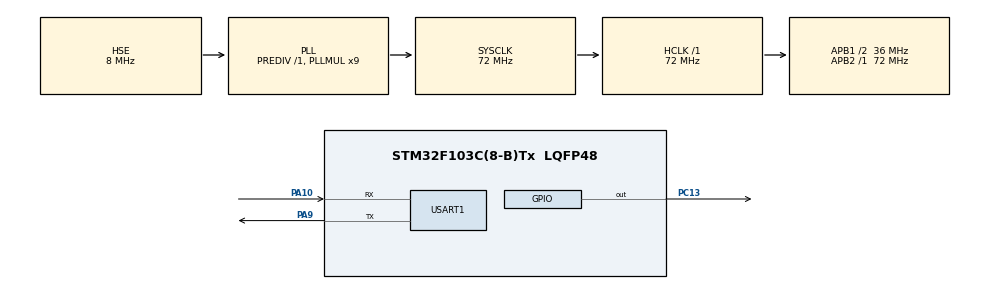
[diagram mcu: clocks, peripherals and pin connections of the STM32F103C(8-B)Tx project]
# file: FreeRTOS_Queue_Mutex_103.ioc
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FREERTOS.Mutexes01=myMutex,Static,myMutexControlBlock
FREERTOS.Queues01=myQueue,16,Zerg,0,Static,myQueueBuffer,myQueueControlBlock
FREERTOS.Tasks01=Print_Task,0,256,Start_Print_Task,Default,NULL,Static,Print_TaskBuffer,Print_TaskControlBlock;my_ON_Task,0,256,Start_ON_Task,Default,NULL,Static,my_ON_TaskBuffer,my_ON_TaskControlBlock;my_OFF_Task,0,256,Start_OFF_Task,Default,NULL,Static,myt_OFF_TaskBuffer,myt_OFF_TaskControlBlock
FREERTOS.configUSE_NEWLIB_REENTRANT=1
Mcu.Family=STM32F1
Mcu.Name=STM32F103C(8-B)Tx
Mcu.Package=LQFP48
NVIC.PriorityGroup=NVIC_PRIORITYGROUP_4
NVIC.TIM4_IRQn=true\:15\:0\:false\:false\:true\:false\:false\:true\:true
NVIC.TimeBase=TIM4_IRQn
NVIC.TimeBaseIP=TIM4
PA10.Mode=Asynchronous
PA10.Signal=USART1_RX
PA13.Mode=Serial_Wire
PA13.Signal=SYS_JTMS-SWDIO
PA14.Mode=Serial_Wire
PA14.Signal=SYS_JTCK-SWCLK
PA9.Mode=Asynchronous
PA9.Signal=USART1_TX
PC13-TAMPER-RTC.Signal=GPIO_Output
PD0-OSC_IN.Mode=HSE-External-Oscillator
PD0-OSC_IN.Signal=RCC_OSC_IN
PD1-OSC_OUT.Mode=HSE-External-Oscillator
PD1-OSC_OUT.Signal=RCC_OSC_OUT
ProjectManager.HeapSize=0x200
ProjectManager.StackSize=0x400
ProjectManager.TargetToolchain=STM32CubeIDE
RCC.AHBFreq_Value=72000000
RCC.APB1CLKDivider=RCC_HCLK_DIV2
RCC.APB1Freq_Value=36000000
RCC.APB1TimFreq_Value=72000000
RCC.APB2Freq_Value=72000000
RCC.APB2TimFreq_Value=72000000
RCC.HCLKFreq_Value=72000000
RCC.PLLMUL=RCC_PLL_MUL9
RCC.PLLSourceVirtual=RCC_PLLSOURCE_HSE
RCC.SYSCLKFreq_VALUE=72000000
RCC.SYSCLKSource=RCC_SYSCLKSOURCE_PLLCLK
RCC.USBFreq_Value=72000000
RTC.Date=11
RTC.Hours=15
RTC.Minutes=30
RTC.Month=RTC_MONTH_APRIL
RTC.WeekDay=RTC_WEEKDAY_TUESDAY
RTC.Year=23
USART1.VirtualMode=VM_ASYNC
VP_FREERTOS_VS_CMSIS_V1.Mode=CMSIS_V1
VP_RTC_VS_RTC_Activate.Mode=RTC_Enabled
VP_RTC_VS_RTC_Calendar.Mode=RTC_Calendar
VP_SYS_VS_tim4.Mode=TIM4
board=custom

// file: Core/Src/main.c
/* USER CODE BEGIN Header */
/**
 ******************************************************************************
 * @file           : main.c
 * @brief          : Main program body
 ******************************************************************************
 * @attention
 *
 * Copyright (c) 2023 STMicroelectronics.
 * All rights reserved.
 *
 * This software is licensed under terms that can be found in the LICENSE file
 * in the root directory of this software component.
 * If no LICENSE file comes with this software, it is provided AS-IS.
 *
 ******************************************************************************
 */
/* USER CODE END Header */
#include "main.h"
#include "cmsis_os.h"

/* USER CODE BEGIN Includes */
#include <stdio.h> /* для printf */

typedef struct {
	char mySharedResource[10];
} Zerg;
/* USER CODE END Includes */

RTC_HandleTypeDef hrtc;

UART_HandleTypeDef huart1;

osThreadId Print_TaskHandle;
uint32_t Print_TaskBuffer[256];
osStaticThreadDef_t Print_TaskControlBlock;
osThreadId my_ON_TaskHandle;
uint32_t my_ON_TaskBuffer[256];
osStaticThreadDef_t my_ON_TaskControlBlock;
osThreadId my_OFF_TaskHandle;
uint32_t myt_OFF_TaskBuffer[256];
osStaticThreadDef_t myt_OFF_TaskControlBlock;
osMessageQId myQueueHandle;
uint8_t myQueueBuffer[16 * sizeof(Zerg)];
osStaticMessageQDef_t myQueueControlBlock;
osMutexId myMutexHandle;
osStaticMutexDef_t myMutexControlBlock;

void SystemClock_Config(void);
static void MX_GPIO_Init(void);
static void MX_RTC_Init(void);
static void MX_USART1_UART_Init(void);
void Start_Print_Task(void const *argument);
void Start_ON_Task(void const *argument);
void Start_OFF_Task(void const *argument);

/* USER CODE BEGIN PFP */
int _write(int file, char *ptr, int len) {
	int i;
	HAL_UART_Transmit(&huart1, (uint8_t*) ptr, len, 50);
	for (i = 0; i < len; i++) {
		ITM_SendChar(*ptr++);
	}
	return len;
}
/* USER CODE END PFP */

int main(void) {

	/* MCU Configuration--------------------------------------------------------*/

	/* Reset of all peripherals, Initializes the Flash interface and the Systick. */
	HAL_Init();

	/* Configure the system clock */
	SystemClock_Config();

	/* Initialize all configured peripherals */
	MX_GPIO_Init();
	MX_RTC_Init();
	MX_USART1_UART_Init();

	/* Create the mutex(es) */
	/* definition and creation of myMutex */
	osMutexStaticDef(myMutex, &myMutexControlBlock);
	myMutexHandle = osMutexCreate(osMutex(myMutex));

	/* Create the queue(s) */
	/* definition and creation of myQueue */
	osMessageQStaticDef(myQueue, 16, Zerg, myQueueBuffer, &myQueueControlBlock);
	myQueueHandle = osMessageCreate(osMessageQ(myQueue), NULL);

	/* Create the thread(s) */
	/* definition and creation of Print_Task */
	osThreadStaticDef(Print_Task, Start_Print_Task, osPriorityNormal, 0, 256,
			Print_TaskBuffer, &Print_TaskControlBlock);
	Print_TaskHandle = osThreadCreate(osThread(Print_Task), NULL);

	/* definition and creation of my_ON_Task */
	osThreadStaticDef(my_ON_Task, Start_ON_Task, osPriorityNormal, 0, 256,
			my_ON_TaskBuffer, &my_ON_TaskControlBlock);
	my_ON_TaskHandle = osThreadCreate(osThread(my_ON_Task), NULL);

	/* definition and creation of my_OFF_Task */
	osThreadStaticDef(my_OFF_Task, Start_OFF_Task, osPriorityNormal, 0, 256,
			myt_OFF_TaskBuffer, &myt_OFF_TaskControlBlock);
	my_OFF_TaskHandle = osThreadCreate(osThread(my_OFF_Task), NULL);

	/* Start scheduler */
	osKernelStart();
	/* We should never get here as control is now taken by the scheduler */
	/* Infinite loop */
	while (1) {

	}
}

void SystemClock_Config(void) {
	RCC_OscInitTypeDef RCC_OscInitStruct = { 0 };
	RCC_ClkInitTypeDef RCC_ClkInitStruct = { 0 };
	RCC_PeriphCLKInitTypeDef PeriphClkInit = { 0 };

	/** Initializes the RCC Oscillators according to the specified parameters
	 * in the RCC_OscInitTypeDef structure.
	 */
	RCC_OscInitStruct.OscillatorType = RCC_OSCILLATORTYPE_LSI
			| RCC_OSCILLATORTYPE_HSE;
	RCC_OscInitStruct.HSEState = RCC_HSE_ON;
	RCC_OscInitStruct.HSEPredivValue = RCC_HSE_PREDIV_DIV1;
	RCC_OscInitStruct.HSIState = RCC_HSI_ON;
	RCC_OscInitStruct.LSIState = RCC_LSI_ON;
	RCC_OscInitStruct.PLL.PLLState = RCC_PLL_ON;
	RCC_OscInitStruct.PLL.PLLSource = RCC_PLLSOURCE_HSE;
	RCC_OscInitStruct.PLL.PLLMUL = RCC_PLL_MUL9;
	if (HAL_RCC_OscConfig(&RCC_OscInitStruct) != HAL_OK) {
		Error_Handler();
	}

	/** Initializes the CPU, AHB and APB buses clocks
	 */
	RCC_ClkInitStruct.ClockType = RCC_CLOCKTYPE_HCLK | RCC_CLOCKTYPE_SYSCLK
			| RCC_CLOCKTYPE_PCLK1 | RCC_CLOCKTYPE_PCLK2;
	RCC_ClkInitStruct.SYSCLKSource = RCC_SYSCLKSOURCE_PLLCLK;
	RCC_ClkInitStruct.AHBCLKDivider = RCC_SYSCLK_DIV1;
	RCC_ClkInitStruct.APB1CLKDivider = RCC_HCLK_DIV2;
	RCC_ClkInitStruct.APB2CLKDivider = RCC_HCLK_DIV1;

	if (HAL_RCC_ClockConfig(&RCC_ClkInitStruct, FLASH_LATENCY_2) != HAL_OK) {
		Error_Handler();
	}
	PeriphClkInit.PeriphClockSelection = RCC_PERIPHCLK_RTC;
	PeriphClkInit.RTCClockSelection = RCC_RTCCLKSOURCE_LSI;
	if (HAL_RCCEx_PeriphCLKConfig(&PeriphClkInit) != HAL_OK) {
		Error_Handler();
	}
}

static void MX_RTC_Init(void) {

	RTC_TimeTypeDef sTime = { 0 };
	RTC_DateTypeDef DateToUpdate = { 0 };

	/** Initialize RTC Only
	 */
	hrtc.Instance = RTC;
	hrtc.Init.AsynchPrediv = RTC_AUTO_1_SECOND;
	hrtc.Init.OutPut = RTC_OUTPUTSOURCE_ALARM;
	if (HAL_RTC_Init(&hrtc) != HAL_OK) {
		Error_Handler();
	}

	/** Initialize RTC and set the Time and Date
	 */
	sTime.Hours = 0x15;
	sTime.Minutes = 0x30;
	sTime.Seconds = 0x0;

	if (HAL_RTC_SetTime(&hrtc, &sTime, RTC_FORMAT_BCD) != HAL_OK) {
		Error_Handler();
	}
	DateToUpdate.WeekDay = RTC_WEEKDAY_TUESDAY;
	DateToUpdate.Month = RTC_MONTH_APRIL;
	DateToUpdate.Date = 0x11;
	DateToUpdate.Year = 0x23;

	if (HAL_RTC_SetDate(&hrtc, &DateToUpdate, RTC_FORMAT_BCD) != HAL_OK) {
		Error_Handler();
	}

}

static void MX_USART1_UART_Init(void) {

	huart1.Instance = USART1;
	huart1.Init.BaudRate = 115200;
	huart1.Init.WordLength = UART_WORDLENGTH_8B;
	huart1.Init.StopBits = UART_STOPBITS_1;
	huart1.Init.Parity = UART_PARITY_NONE;
	huart1.Init.Mode = UART_MODE_TX_RX;
	huart1.Init.HwFlowCtl = UART_HWCONTROL_NONE;
	huart1.Init.OverSampling = UART_OVERSAMPLING_16;
	if (HAL_UART_Init(&huart1) != HAL_OK) {
		Error_Handler();
	}

}

static void MX_GPIO_Init(void) {
	GPIO_InitTypeDef GPIO_InitStruct = { 0 };

	/* GPIO Ports Clock Enable */
	__HAL_RCC_GPIOC_CLK_ENABLE();
	__HAL_RCC_GPIOD_CLK_ENABLE();
	__HAL_RCC_GPIOA_CLK_ENABLE();

	/*Configure GPIO pin Output Level */
	HAL_GPIO_WritePin(GPIOC, GPIO_PIN_13, GPIO_PIN_RESET);

	/*Configure GPIO pin : PC13 */
	GPIO_InitStruct.Pin = GPIO_PIN_13;
	GPIO_InitStruct.Mode = GPIO_MODE_OUTPUT_PP;
	GPIO_InitStruct.Pull = GPIO_NOPULL;
	GPIO_InitStruct.Speed = GPIO_SPEED_FREQ_LOW;
	HAL_GPIO_Init(GPIOC, &GPIO_InitStruct);

}

void Start_Print_Task(void const *argument) {
	/* USER CODE BEGIN 5 */
	Zerg data;
	/* Infinite loop */
	for (;;) {
		if (xQueueReceive(myQueueHandle, &data,portMAX_DELAY) == pdTRUE) {/* portMAX_DELAY - Если очередь пустая то, Task будет ждать пока не появятся данные!  == pdTRUE - проверка на ошибки при получении!*/
			printf("data_GET : %s \r\n", data.mySharedResource);
//		osDelay(1);
		}
	}
	/* USER CODE END 5 */
}

void Start_ON_Task(void const *argument) {
	/* USER CODE BEGIN Start_ON_Task */
	char potetoesMsg[] = "potatoes";
	int i;
	Zerg data;
	/* Infinite loop */
	for (;;) {
// Ниже критическая зона которую прерывать нельзя!
		if (xSemaphoreTake(myMutexHandle, portMAX_DELAY) == 1) { // Берем ключ/Mutex от "шкафчика" если он свободен!

			for (i = 0; i < 9; i++) {
				data.mySharedResource[i] = potetoesMsg[i];
				osDelay(50);
			}
			data.mySharedResource[i] = 0;

			/************* Отправляем в очередь *******************/
			if ( xQueueSend( myQueueHandle,&data.mySharedResource, portMAX_DELAY) != pdPASS) { // Если очередь полная то, Task будет ждать пока освободится очередь!
				printf("Attention, the queue is full! No place for 'ON'. \n\r"); /* Failed to post the message, even after 500 ticks. */
			}

//			printf("potetoesMsg : %s \r\n", data.mySharedResource);
			xSemaphoreGive(myMutexHandle); // Возвращаем ключ! Выход из критической зоны.
		}
		osDelay(1);
	}
	/* USER CODE END Start_ON_Task */
}

void Start_OFF_Task(void const *argument) {
	/* USER CODE BEGIN Start_OFF_Task */
	char tomatoesMsg[] = "tomatoes";
	int i;
	Zerg data;
	/* Infinite loop */
	for (;;) {
		// Ниже критическая зона которую прерывать нельзя!
		if (xSemaphoreTake(myMutexHandle, portMAX_DELAY) == 1) { // Берем ключ/Mutex от "шкафчика" если он свободен!
			for (i = 0; i < 9; i++) {
				data.mySharedResource[i] = tomatoesMsg[i];
				osDelay(50);
			}
			data.mySharedResource[i] = 0;

			/************* Отправляем  в очередь *******************/
			if ( xQueueSend( myQueueHandle,&data.mySharedResource, portMAX_DELAY) != pdPASS) { // Если очередь полная то, Task будет ждать пока освободится очередь!
				printf("Attention, the queue is full! No place for 'ON'. \n\r"); /* Failed to post the message, even after 500 ticks. */
			}

//			printf("tomatoesMsg : %s\r\n", data.mySharedResource);
			xSemaphoreGive(myMutexHandle); // Возвращаем ключ! Выход из критической зоны.
		}
		osDelay(1);
	}
	/* USER CODE END Start_OFF_Task */
}

void HAL_TIM_PeriodElapsedCallback(TIM_HandleTypeDef *htim) {
	if (htim->Instance == TIM4) {
		HAL_IncTick();
	}
}

void Error_Handler(void) {
	__disable_irq();
	while (1) {
	}
}
